# RL7005_IP_SVD register map
Vendor: Realtek
Registers are 32-bit, read-write, reset 0x0 unless marked. A register's access mark holds for its fields unless they carry their own. Offsets are from the block's base; [hi:lo] are bit positions; lines under a group give offsets from that group; {n}, {i} and the like mark numbered series.

## RXI300_REG
Base 0x41002000
Same registers: MPC1_S 0x51002200, MPC2_S 0x51002300, MPC3_S 0x51002400, PPC_S 0x51002500
0x00 NAME ro reset 0x52300 — RXI300 design name register
  [31:0] NAME — The design name of RXI-300.
0x04 VER ro reset 0x300 — RXI300 design version register
  [31:0] VER — The design version of RXI-300.
0x08 RVE ro reset 0x1 — RXI300 design reversion register
  [31:0] REV — The design reversion of RXI-300.
0x0C INST ro — RXI300 design instance number register
  [31:0] INST — The design instance number of RXI-300.
0x10 IMPL_Y ro reset 0x2024 — RXI300 implementation year register
  [31:0] IMPL_Y — The implementatin year of RXI-300. Reset value depends on implementation date.
0x14 IMPL_D ro reset 0x5101058 — RXI300 implementation date register
  [31:0] IMPL_D — The implementatin date of RXI-300. Reset value depends on implementation date.
0x18 DEV ro reset 0x5207433 — RXI300 developer register
  [31:0] DEV — The developer of RXI-300.
0x1C PRO_NUM ro reset 0x7005 — RXI300 project number register
  [31:0] PRO_NUM — The project number of RXI-300.
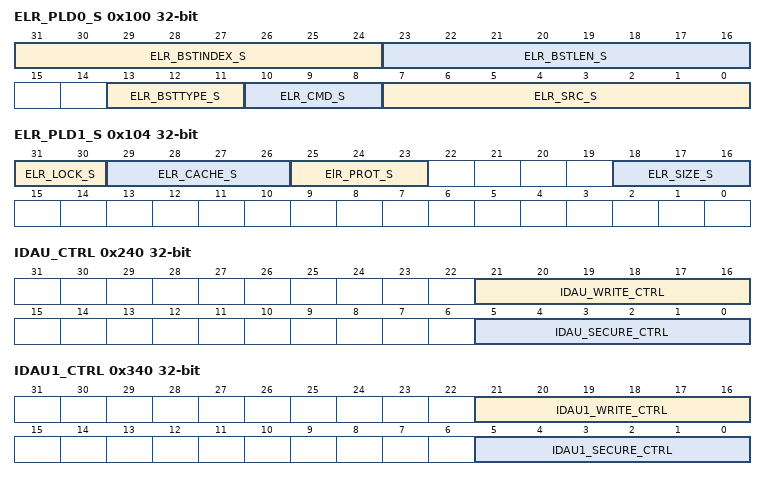
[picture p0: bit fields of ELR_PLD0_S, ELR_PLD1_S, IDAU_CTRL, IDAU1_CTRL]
0x100 ELR_PLD0_S ro — Error log payload register0
  [31:24] ELR_BSTINDEX_S — Burst index of the error request.
  [23:16] ELR_BSTLEN_S — Burst Length of the error request.
  [13:11] ELR_BSTTYPE_S — BurstSeq of the error request.
  [10:8] ELR_CMD_S — CMD of the error request. 0x1: Write command 0x2: Read command
  [7:0] ELR_SRC_S — Error source of the error request. 0x10: S1 securedefault slave 0x20: S2 securedefault slave 0x30: S3-0~1,5,7(AHB) group secure default slave 0x31: S3-2~4,6,13~22(AHB) group secure default slave 0x32: S3-8(AXI) secure default slave 0x33:S3-9~10(SPIC)group secure default slave 0x34: S3-11~12(PSRAM)group secure default slave 0x60: S4-0~6 secure default slave 0x61: S4-7~15 secure default slave 0x70: S5 secure default slave 0x71: MPC/PPC secure default slave 0x80: S8 secure default slave
0x104 ELR_PLD1_S ro — Error log payload register1
  [31:30] ELR_LOCK_S — AxLock of the error request.
  [29:26] ELR_CACHE_S — AxCache of the error request.
  [25:23] ElR_PROT_S — AxProt of the error request.
  [18:16] ELR_SIZE_S — Size of the error request.
0x108 ELR_ID_S ro — Error log ID information register
  [31:0] ELR_ID_S — Tagid of the error request. 9'b00000????: M0 access error 9'b00001????: M1 access error 9'b0100?????: M2 access error 9'b000110???: M3 access error 9'b0001010??: M4 access error 9'b000100110: M5-0 access error 9'b000100111: M5-1 access error 9'b0101?????: M6 access error 9'b1????????: M7 access error 9'b00010000?: M8 access error 9'b00010010: M9 access error 9'b00010001: M10 access error 9'b011000???: M11 access error
0x10C ELR_ADR0_S ro — Error log addrress register0
  [31:0] ELR_ADR0_S — Address[31:0] of the error request.
0x110 ELR_ADR1_S ro — Error log addrress register1
  [63:32] ELR_ADR1_S — Address[63:32] of the error request.
0x130 ELR_CODE_S ro — Error code register
  [7:0] ELR_CODE_S — The error code of error request, if it's 0, indicates that there is no error request. 8'h00: No error 8'h02: Secure fault error
0x13C ELR_INTR_CLR_S wo — Error log clear register
  [0] ELR_INTR_CLR_S — Error log interrupt clear. Writing 1'b1 to the register will trigger a 1-cycle pulse interrupt clear. It has to write 1'b1 to this register every time when the error exception occurs. Note that this register is write-only, the return value of reading this register is meaningless.
{0x200+8i} IDAU_BA{i} (i=0..5) — Base address register {i} in IDAU
  [27:12] IDAU_BA{i} — It's the base address of region {i} which can be set as non-secure. [11:0]: reserved [27:12]: base address of region {i} [31:28]: reserved
{0x204+8i} IDAU_LA{i} reset 0xFFFF000 (i=0..5) — Top address register {i} in IDAU
  [27:12] IDAU_LA{i} — It's the top address of region {i} which can be set as non-secure. [11:0]: reserved [27:12]: top address of region {i} [31:28]: reserved
0x240 IDAU_CTRL — Enable control register in IDAU
  [21:16] IDAU_WRITE_CTRL — Region entry enable After setting WRITE_CTRL bits as 1, corresponding regions is set as write-forbidden.Note that if WRITE_CTRL bits are enabled, the region remains secure even if ba*i/la*i is set. [16]: enable entry for ba0/la0 0: disable 1: enable [17]: enable entry for ba1/la1 0: disable 1: enable [18]: enable entry for ba2/la2 0: disable 1: enable [19]: enable entry for ba3/la3 0: disable 1: enable [20]: enable entry for ba4/la4 0: disable 1: enable [21]: enable entry for ba5/la5 0: disable 1: enable
  [5:0] IDAU_SECURE_CTRL — Region entry enable After setting SECURE_CTRL bits as 1, corresponding regions is set as non-secure.Note that if SECURE_CTRL bits are enabled, the region remains secure even if ba*i/la*i is set. [0]: enable entry for ba0/la0 0: disable 1: enable [1]: enable entry for ba1/la1 0: disable 1: enable [2]: enable entry for ba2/la2 0: disable 1: enable [3]: enable entry for ba3/la3 0: disable 1: enable [4]: enable entry for ba4/la4 0: disable 1: enable [5]: enable entry for ba5/la5 0: disable 1: enable
0x244 IDAU_LOCK — Lock control register in IDAU
  [0] IDAU_LOCK — Lock write transfer for all registers in IDAU (including lock register itself) until system reset if it is ebabled. 0: disable lock 1: enable lock
{0x300+8i} IDAU1_BA{i} (i=0..5) — Base address register {i} in IDAU1
  [27:12] IDAU1_BA{i} — It's the base address of region {i} which can be set as non-secure. [11:0]: reserved [27:12]: base address of region {i} [31:28]: reserved
{0x304+8i} IDAU1_LA{i} reset 0xFFFF000 (i=0..5) — Top address register {i} in IDAU1
  [27:12] IDAU1_LA{i} — It's the top address of region {i} which can be set as non-secure. [11:0]: reserved [27:12]: top address of region {i} [31:28]: reserved
0x340 IDAU1_CTRL — Enable control register in IDAU1
  [21:16] IDAU1_WRITE_CTRL — Region entry enable After setting WRITE_CTRL bits as 1, corresponding regions is set as write-forbidden.Note that if WRITE_CTRL bits are enabled, the region remains secure even if ba*i/la*i is set. [16]: enable entry for ba0/la0 0: disable 1: enable [17]: enable entry for ba1/la1 0: disable 1: enable [18]: enable entry for ba2/la2 0: disable 1: enable [19]: enable entry for ba3/la3 0: disable 1: enable [20]: enable entry for ba4/la4 0: disable 1: enable [21]: enable entry for ba5/la5 0: disable 1: enable
  [5:0] IDAU1_SECURE_CTRL — Region entry enable After setting SECURE_CTRL bits as 1, corresponding regions is set as non-secure.Note that if SECURE_CTRL bits are enabled, the region remains secure even if ba*i/la*i is set. [0]: enable entry for ba0/la0 0: disable 1: enable [1]: enable entry for ba1/la1 0: disable 1: enable [2]: enable entry for ba2/la2 0: disable 1: enable [3]: enable entry for ba3/la3 0: disable 1: enable [4]: enable entry for ba4/la4 0: disable 1: enable [5]: enable entry for ba5/la5 0: disable 1: enable
0x344 IDAU1_LOCK — Lock control register in IDAU1
  [0] IDAU1_LOCK — Lock write transfer for all registers in IDAU1 (including lock register itself) until system reset if it is ebabled. 0: disable lock 1: enable lock
{0x400+8i} IDAU2_BA{i} (i=0..5) — Base address register {i} in IDAU2
  [27:12] IDAU2_BA{i} — It's the base address of region {i} which can be set as non-secure. [11:0]: reserved [27:12]: base address of region {i} [31:28]: reserved
{0x404+8i} IDAU2_LA{i} reset 0xFFFF000 (i=0..5) — Top address register {i} in IDAU2
  [27:12] IDAU2_LA{i} — It's the top address of region {i} which can be set as non-secure. [11:0]: reserved [27:12]: top address of region {i} [31:28]: reserved
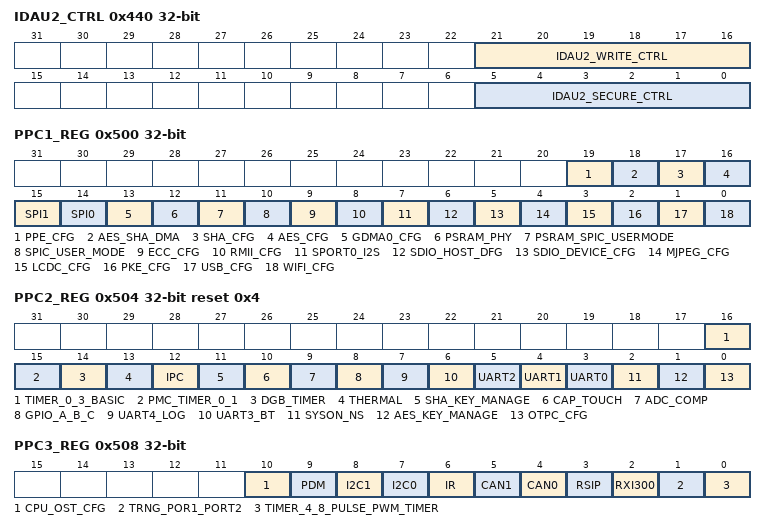
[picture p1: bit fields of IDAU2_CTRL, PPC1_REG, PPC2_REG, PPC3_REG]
0x440 IDAU2_CTRL — Enable control register in IDAU2
  [21:16] IDAU2_WRITE_CTRL — Region entry enable After setting WRITE_CTRL bits as 1, corresponding regions is set as write-forbidden.Note that if WRITE_CTRL bits are enabled, the region remains secure even if ba*i/la*i is set. [16]: enable entry for ba0/la0 0: disable 1: enable [17]: enable entry for ba1/la1 0: disable 1: enable [18]: enable entry for ba2/la2 0: disable 1: enable [19]: enable entry for ba3/la3 0: disable 1: enable [20]: enable entry for ba4/la4 0: disable 1: enable [21]: enable entry for ba5/la5 0: disable 1: enable
  [5:0] IDAU2_SECURE_CTRL — Region entry enable After setting SECURE_CTRL bits as 1, corresponding regions is set as non-secure.Note that if SECURE_CTRL bits are enabled, the region remains secure even if ba*i/la*i is set. [0]: enable entry for ba0/la0 0: disable 1: enable [1]: enable entry for ba1/la1 0: disable 1: enable [2]: enable entry for ba2/la2 0: disable 1: enable [3]: enable entry for ba3/la3 0: disable 1: enable [4]: enable entry for ba4/la4 0: disable 1: enable [5]: enable entry for ba5/la5 0: disable 1: enable
0x444 IDAU2_LOCK — Lock control register in IDAU2
  [0] IDAU2_LOCK — Lock write transfer for all registers in IDAU2 (including lock register itself) until system reset if it is ebabled. 0: disable lock 1: enable lock
0x500 PPC1_REG — PPC1 configure register0
  [19] PPE_CFG — 1: Non-secure attribution 0: Secure attribution
  [18] AES_SHA_DMA — 1: Non-secure attribution 0: Secure attribution
  [17] SHA_CFG — 1: Non-secure attribution 0: Secure attribution
  [16] AES_CFG — 1: Non-secure attribution 0: Secure attribution
  [15] SPI1 — 1: Non-secure attribution 0: Secure attribution
  [14] SPI0 — 1: Non-secure attribution 0: Secure attribution
  [13] GDMA0_CFG — 1: Non-secure attribution 0: Secure attribution
  [12] PSRAM_PHY — 1: Non-secure attribution 0: Secure attribution
  [11] PSRAM_SPIC_USERMODE — 1: Non-secure attribution 0: Secure attribution
  [10] SPIC_USER_MODE — 1: Non-secure attribution 0: Secure attribution
  [9] ECC_CFG — 1: Non-secure attribution 0: Secure attribution
  [8] RMII_CFG — 1: Non-secure attribution 0: Secure attribution
  [7] SPORT0_I2S — 1: Non-secure attribution 0: Secure attribution
  [6] SDIO_HOST_DFG — 1: Non-secure attribution 0: Secure attribution
  [5] SDIO_DEVICE_CFG — 1: Non-secure attribution 0: Secure attribution
  [4] MJPEG_CFG — 1: Non-secure attribution 0: Secure attribution
  [3] LCDC_CFG — 1: Non-secure attribution 0: Secure attribution
  [2] PKE_CFG — 1: Non-secure attribution 0: Secure attribution
  [1] USB_CFG — 1: Non-secure attribution 0: Secure attribution
  [0] WIFI_CFG — 1: Non-secure attribution 0: Secure attribution
0x504 PPC2_REG reset 0x4 — PPC2 configure register
  [16] TIMER_0_3_BASIC — 1: Non-secure attribution 0: Secure attribution
  [15] PMC_TIMER_0_1 — 1: Non-secure attribution 0: Secure attribution
  [14] DGB_TIMER — 1: Non-secure attribution 0: Secure attribution
  [13] THERMAL — 1: Non-secure attribution 0: Secure attribution
  [12] IPC — 1: Non-secure attribution 0: Secure attribution
  [11] SHA_KEY_MANAGE — 1: Non-secure attribution 0: Secure attribution
  [10] CAP_TOUCH — 1: Non-secure attribution 0: Secure attribution
  [9] ADC_COMP — 1: Non-secure attribution 0: Secure attribution
  [8] GPIO_A_B_C — 1: Non-secure attribution 0: Secure attribution
  [7] UART4_LOG — 1: Non-secure attribution 0: Secure attribution
  [6] UART3_BT — 1: Non-secure attribution 0: Secure attribution
  [5] UART2 — 1: Non-secure attribution 0: Secure attribution
  [4] UART1 — 1: Non-secure attribution 0: Secure attribution
  [3] UART0 — 1: Non-secure attribution 0: Secure attribution
  [2] SYSON_NS — 1: Non-secure attribution 0: Secure attribution
  [1] AES_KEY_MANAGE — 1: Non-secure attribution 0: Secure attribution
  [0] OTPC_CFG — 1: Non-secure attribution 0: Secure attribution
0x508 PPC3_REG — PPC3 configure register
  [10] CPU_OST_CFG — 1: Non-secure attribution 0: Secure attribution
  [9] PDM — 1: Non-secure attribution 0: Secure attribution
  [8] I2C1 — 1: Non-secure attribution 0: Secure attribution
  [7] I2C0 — 1: Non-secure attribution 0: Secure attribution
  [6] IR — 1: Non-secure attribution 0: Secure attribution
  [5] CAN1 — 1: Non-secure attribution 0: Secure attribution
  [4] CAN0 — 1: Non-secure attribution 0: Secure attribution
  [3] RSIP — 1: Non-secure attribution 0: Secure attribution
  [2] RXI300 — 1: Non-secure attribution 0: Secure attribution
  [1] TRNG_POR1_PORT2 — 1: Non-secure attribution 0: Secure attribution
  [0] TIMER_4_8_PULSE_PWM_TIMER — 1: Non-secure attribution 0: Secure attribution
0x50C PPC_LOCK
  [0] LOCK — PPC lock register. When writing 1'b1 to this nit, PPC will be locked. Note: It can not be written to 1'b0 again until system reset to prevent modification. When PPC is locked, you can not program PPC registers unless system reset.
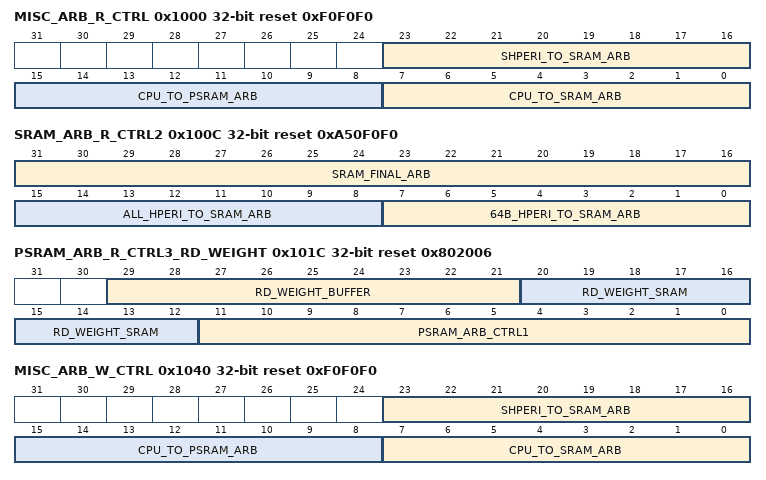
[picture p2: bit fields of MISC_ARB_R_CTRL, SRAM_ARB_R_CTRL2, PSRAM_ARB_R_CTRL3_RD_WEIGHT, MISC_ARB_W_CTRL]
0x1000 MISC_ARB_R_CTRL reset 0xF0F0F0 — The register for CPU/HPERI to SRAM/PSRAM read arbitration
  [23:16] SHPERI_TO_SRAM_ARB — Read arbitration control register. Each slot should be set by a port number. The port number represents a master group.The master group is shown as following: 0x0: LCDC 0x1: PPE And the following shows bit field of each slots: [0]: slot 0 of arbiter [1]: slot 1 of arbiter [2]: slot 2 of arbiter [3]: slot 3 of arbiter [4]: slot 4 of arbiter [5]: slot 5 of arbiter [6]: slot 6 of arbiter [7]: slot 7 of arbiter
  [15:8] CPU_TO_PSRAM_ARB — Read arbitration control register. Each slot should be set by a port number. The port number represents a master group.The master group is shown as following: 0x0: CPU0 0x1: CPU1 And the following shows bit field of each slots: [0]: slot 0 of arbiter [1]: slot 1 of arbiter [2]: slot 2 of arbiter [3]: slot 3 of arbiter [4]: slot 4 of arbiter [5]: slot 5 of arbiter [6]: slot 6 of arbiter [7]: slot 7 of arbiter
  [7:0] CPU_TO_SRAM_ARB — Read arbitration control register. Each slot should be set by a port number. The port number represents a master group.The master group is shown as following: 0x0: CPU0 0x1: CPU1 And the following shows bit field of each slots: [0]: slot 0 of arbiter [1]: slot 1 of arbiter [2]: slot 2 of arbiter [3]: slot 3 of arbiter [4]: slot 4 of arbiter [5]: slot 5 of arbiter [6]: slot 6 of arbiter [7]: slot 7 of arbiter
0x1004 SRAM_ARB_R_CTRL0 reset 0x2D91A240 — The register for 32-bit HPERI master group to SRAM read arbitration
  [29:0] 32B_HPERI_TO_SRAM_ARB — Read arbitration control register. Each slot should be set by a port number. The port number represents a master group.The master group is shown as following: 0x0: GDMA 0x1: WIFI 0x2: USB/SDIO_BT/SDIO_WIFI 0x3: OTPC/SIC 0x4: SDIO_HOST 0x5: RMII And the following shows bit field of each slots: [2:0]: slot 0 of arbiter [5:3]: slot 1 of arbiter [8:6]: slot 2 of arbiter [11:9]: slot 3 of arbiter [14:12]: slot 4 of arbiter [17:15]: slot 5 of arbiter [20:18]: slot 6 of arbiter [23:21]: slot 7 of arbiter [26:24]: slot 8 of arbiter [29:27]: slot 9 of arbiter
0x1008 SRAM_ARB_R_CTRL1 reset 0x2D91A240 — The register for 32-bit HPERI master group to SRAM read arbitration
  [29:0] 32B_HPERI_TO_SRAM_ARB — This is extended register of 32B_HPERI_TO_SRAM_ARB [2:0]: slot 0 of arbiter [5:3]: slot 1 of arbiter [8:6]: slot 2 of arbiter [11:9]: slot 3 of arbiter [14:12]: slot 4 of arbiter [17:15]: slot 5 of arbiter [20:18]: slot 6 of arbiter [23:21]: slot 7 of arbiter [26:24]: slot 8 of arbiter [29:27]: slot 9 of arbiter
0x100C SRAM_ARB_R_CTRL2 reset 0xA50F0F0 — The register for CPU/LCDC/HPERI master group to SRAM read arbitration
  [31:16] SRAM_FINAL_ARB — Read arbitration control register. Each slot should be set by a port number. The port number represents a master group.The master group is shown as following: 0x0: CPU_TO_SRAM_ARB group 0x1: ALL_HPERI_TO_SRAM_ARB group 0x2: SHPERI_TO_SRAM_ARB group And the following shows bit field of each slots: [1:0]: slot 0 of arbiter [3:2]: slot 1 of arbiter [5:4]: slot 2 of arbiter [7:6]: slot 3 of arbiter [9:8]: slot 4 of arbiter [11:10]: slot 5 of arbiter [13:12]: slot 6 of arbiter [15:14]: slot 7 of arbiter
  [15:8] ALL_HPERI_TO_SRAM_ARB — Read arbitration control register. Each slot should be set by a port number. The port number represents a master group.The master group is shown as following: 0x0: 32B_HPERI_TO_SRAM_ARB group 0x1: 64B_HPERI_TO_SRAM_ARB group And the following shows bit field of each slots: [0]: slot 0 of arbiter [1]: slot 1 of arbiter [2]: slot 2 of arbiter [3]: slot 3 of arbiter [4]: slot 4 of arbiter [5]: slot 5 of arbiter [6]: slot 6 of arbiter [7]: slot 7 of arbiter
  [7:0] 64B_HPERI_TO_SRAM_ARB — Read arbitration control register. Each slot should be set by a port number. The port number represents a master group.The master group is shown as following: 0x0: AES_SHA 0x1: MJPEG And the following shows bit field of each slots: [0]: slot 0 of arbiter [1]: slot 1 of arbiter [2]: slot 2 of arbiter [3]: slot 3 of arbiter [4]: slot 4 of arbiter [5]: slot 5 of arbiter [6]: slot 6 of arbiter [7]: slot 7 of arbiter
0x1010 PSRAM_ARB_R_CTRL0 reset 0x246D2240 — The register for no performance requirement master group to PSRAM read arbitration
  [29:0] HPERI_TO_PSRAM_ARB — Read arbitration control register. Each slot should be set by a port number. The port number represents a master group.The master group is shown as following: 0x0: GDMA 0x1: OTPC/SIC 0x2: AED_SHA 0x3: SDIO_HOST 0x4: RMII And the following shows bit field of each slots: [2:0]: slot 0 of arbiter [5:3]: slot 1 of arbiter [8:6]: slot 2 of arbiter [11:9]: slot 3 of arbiter [14:12]: slot 4 of arbiter [17:15]: slot 5 of arbiter [20:18]: slot 6 of arbiter [23:21]: slot 7 of arbiter [26:24]: slot 8 of arbiter [29:27]: slot 9 of arbiter
0x1014 PSRAM_ARB_R_CTRL1 reset 0x1A489200 — The register for PSRAM read arbitration
  [29:0] R_CTRL1_PSRAM_FINAL_ARB — Read arbitration control register. Each slot should be set by a port number. The port number represents a master group.The master group is shown as following: 0x0: CPU0/CPU1 0x1: HPERI_TO_PSRAM_ARB group 0x2: WIFI 0x3: USB 0x4: MJPEG 0x5: LCDC 0x6: PPE And the following shows bit field of each slots: [2:0]: slot 0 of arbiter [5:3]: slot 1 of arbiter [8:6]: slot 2 of arbiter [11:9]: slot 3 of arbiter [14:12]: slot 4 of arbiter [17:15]: slot 5 of arbiter [20:18]: slot 6 of arbiter [23:21]: slot 7 of arbiter [26:24]: slot 8 of arbiter [29:27]: slot 9 of arbiter
0x1018 PSRAM_ARB_R_CTRL2 reset 0x36B6C91B — The register for PSRAM read arbitration
  [29:0] R_CTRL2_PSRAM_FINAL_ARB — This is extended register of PSRAM_FINAL_ARB slot [2:0]: slot 10 of arbiter [5:3]: slot 11 of arbiter [8:6]: slot 12 of arbiter [11:9]: slot 13 of arbiter [14:12]: slot 14 of arbiter [17:15]: slot 15 of arbiter [20:18]: slot 16 of arbiter [23:21]: slot 17 of arbiter [26:24]: slot 18 of arbiter [29:27]: slot 19 of arbiter
0x101C PSRAM_ARB_R_CTRL3_RD_WEIGHT reset 0x802006 — The register for PSRAM read arbitration and weight control of SRAM controller
  [29:21] RD_WEIGHT_BUFFER — Read CMD weight of buffer_ram
  [20:12] RD_WEIGHT_SRAM — Read CMD weight of hs_sram0
  [11:0] PSRAM_ARB_CTRL1 — This is extended register of PSRAM_ARB_CTRL0 slot. [3:0]: slot 8 of arbiter [7:4]: slot 9 of arbiter [11:8]: slot 10 of arbiter [15:12]: slot 11 of arbiter [19:16]: slot 12 of arbiter [23:20]: slot 13 of arbiter [27:24]: slot 14 of arbiter [31:28]: slot 15 of arbiter
0x1040 MISC_ARB_W_CTRL reset 0xF0F0F0 — The register for CPU/SHPERI to SRAM/PSRAM write arbitration
  [23:16] SHPERI_TO_SRAM_ARB — Write arbitration control register. Each slot should be set by a port number. The port number represents a master group.The master group is shown as following: 0x0: LCDC 0x1: PPE And the following shows bit field of each slots: [0]: slot 0 of arbiter [1]: slot 1 of arbiter [2]: slot 2 of arbiter [3]: slot 3 of arbiter [4]: slot 4 of arbiter [5]: slot 5 of arbiter [6]: slot 6 of arbiter [7]: slot 7 of arbiter
  [15:8] CPU_TO_PSRAM_ARB — Write arbitration control register. Each slot should be set by a port number. The port number represents a master group.The master group is shown as following: 0x0: CPU0 0x1: CPU1 And the following shows bit field of each slots: [0]: slot 0 of arbiter [1]: slot 1 of arbiter [2]: slot 2 of arbiter [3]: slot 3 of arbiter [4]: slot 4 of arbiter [5]: slot 5 of arbiter [6]: slot 6 of arbiter [7]: slot 7 of arbiter
  [7:0] CPU_TO_SRAM_ARB — Write arbitration control register. Each slot should be set by a port number. The port number represents a master group.The master group is shown as following: 0x0: CPU0 0x1: CPU1 And the following shows bit field of each slots: [0]: slot 0 of arbiter [1]: slot 1 of arbiter [2]: slot 2 of arbiter [3]: slot 3 of arbiter [4]: slot 4 of arbiter [5]: slot 5 of arbiter [6]: slot 6 of arbiter [7]: slot 7 of arbiter
0x1044 SRAM_ARB_W_CTRL0 reset 0x2D91A240 — The register 32-bit HPERI master group to SRAM write arbitration
  [29:0] 32B_HPERI_TO_SRAM_ARB — Write arbitration control register. Each slot should be set by a port number. The port number represents a master group.The master group is shown as following: 0x0: GDMA 0x1: WIFI 0x2: USB/SDIO_BT/SDIO_WIFI 0x3: OTPC/SIC 0x4: SDIO_HOST 0x5: RMII And the following shows bit field of each slots: [2:0]: slot 0 of arbiter [5:3]: slot 1 of arbiter [8:6]: slot 2 of arbiter [11:9]: slot 3 of arbiter [14:12]: slot 4 of arbiter [17:15]: slot 5 of arbiter [20:18]: slot 6 of arbiter [23:21]: slot 7 of arbiter [26:24]: slot 8 of arbiter [29:27]: slot 9 of arbiter
0x1048 SRAM_ARB_W_CTRL1 reset 0x2D91A240 — The register 32-bit HPERI master group to SRAM write arbitration
  [29:0] 32B_HPERI_TO_SRAM_ARB — This is extended register of 32B_HPERI_TO_SRAM_ARB [2:0]: slot 10 of arbiter [5:3]: slot 11 of arbiter [8:6]: slot 12 of arbiter [11:9]: slot 13 of arbiter [14:12]: slot 14 of arbiter [17:15]: slot 15 of arbiter [20:18]: slot 16 of arbiter [23:21]: slot 17 of arbiter [26:24]: slot 18 of arbiter [29:27]: slot 19 of arbiter
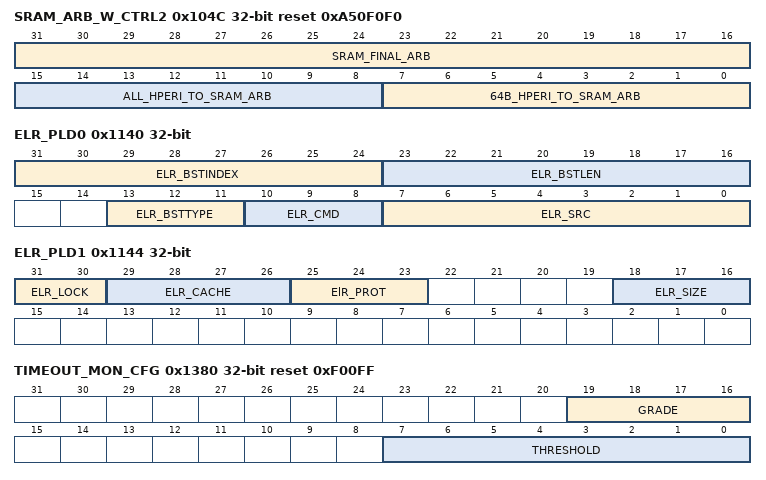
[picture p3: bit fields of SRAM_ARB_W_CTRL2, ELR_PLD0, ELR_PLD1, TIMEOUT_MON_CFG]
0x104C SRAM_ARB_W_CTRL2 reset 0xA50F0F0 — The register for CPU/LCD/ HPERI master group to SRAM write arbitration
  [31:16] SRAM_FINAL_ARB — Write arbitration control register. Each slot should be set by a port number. The port number represents a master group.The master group is shown as following: 0x0: CPU_TO_SRAM_ARB group 0x1: ALL_HPERI_TO_SRAM_ARB group 0x2: SHPERI_TO_SRAM_ARB group And the following shows bit field of each slots: [1:0]: slot 0 of arbiter [3:2]: slot 1 of arbiter [5:4]: slot 2 of arbiter [7:6]: slot 3 of arbiter [9:8]: slot 4 of arbiter [11:10]: slot 5 of arbiter [13:12]: slot 6 of arbiter [15:14]: slot 7 of arbiter
  [15:8] ALL_HPERI_TO_SRAM_ARB — Write arbitration control register. Each slot should be set by a port number. The port number represents a master group.The master group is shown as following: 0x0: 32B_HPERI_TO_SRAM_ARB group 0x1: 64B_HPERI_TO_SRAM_ARB group And the following shows bit field of each slots: [0]: slot 0 of arbiter [1]: slot 1 of arbiter [2]: slot 2 of arbiter [3]: slot 3 of arbiter [4]: slot 4 of arbiter [5]: slot 5 of arbiter [6]: slot 6 of arbiter [7]: slot 7 of arbiter
  [7:0] 64B_HPERI_TO_SRAM_ARB — Write arbitration control register. Each slot should be set by a port number. The port number represents a master group.The master group is shown as following: 0x0: AES_SHA 0x1: MJPEG And the following shows bit field of each slots: [0]: slot 0 of arbiter [1]: slot 1 of arbiter [2]: slot 2 of arbiter [3]: slot 3 of arbiter [4]: slot 4 of arbiter [5]: slot 5 of arbiter [6]: slot 6 of arbiter [7]: slot 7 of arbiter
0x1050 PSRAM_ARB_W_CTRL0 reset 0x246D2240 — The register for performance requirement master group to PSRAM write arbitration
  [29:0] HPERI_TO_PSRAM_ARB — Write arbitration control register. Each slot should be set by a port number. The port number represents a master group.The master group is shown as following: 0x0: GDMA 0x1: OTPC/SIC 0x2: AED_SHA 0x3: SDIO_HOST 0x4: RMII And the following shows bit field of each slots: [2:0]: slot 0 of arbiter [5:3]: slot 1 of arbiter [8:6]: slot 2 of arbiter [11:9]: slot 3 of arbiter [14:12]: slot 4 of arbiter [17:15]: slot 5 of arbiter [20:18]: slot 6 of arbiter [23:21]: slot 7 of arbiter [26:24]: slot 8 of arbiter [29:27]: slot 9 of arbiter
0x1054 PSRAM_ARB_W_CTRL1 reset 0x1A489200 — The register for PSRAM write arbitration
  [29:0] W_CTRL1_PSRAM_FINAL_ARB — Write arbitration control register. Each slot should be set by a port number. The port number represents a master group.The master group is shown as following: 0x0: CPU0/CPU1 0x1: HPERI_TO_PSRAM_ARB group 0x2: WIFI 0x3: USB 0x4: MJPEG 0x5: LCDC 0x6: PPE And the following shows bit field of each slots: [2:0]: slot 0 of arbiter [5:3]: slot 1 of arbiter [8:6]: slot 2 of arbiter [11:9]: slot 3 of arbiter [14:12]: slot 4 of arbiter [17:15]: slot 5 of arbiter [20:18]: slot 6 of arbiter [23:21]: slot 7 of arbiter [26:24]: slot 8 of arbiter [29:27]: slot 9 of arbiter
0x1058 PSRAM_ARB_W_CTRL2 reset 0x36B6C91B — The register for PSRAM write arbitration
  [29:0] W_CTRL2_PSRAM_FINAL_ARB — This is extended register of PSRAM_FINAL_ARB slot [2:0]: slot 10 of arbiter [5:3]: slot 11 of arbiter [8:6]: slot 12 of arbiter [11:9]: slot 13 of arbiter [14:12]: slot 14 of arbiter [17:15]: slot 15 of arbiter [20:18]: slot 16 of arbiter [23:21]: slot 17 of arbiter [26:24]: slot 18 of arbiter [29:27]: slot 19 of arbiter
0x105C PSRAM_ARB_W_CTRL3 reset 0x6 — The register for PSRAM write arbitration
  [11:0] W_CTRL3_PSRAM_FINAL_ARB — This is extended register of PSRAM_FINAL_ARB slot. [2:0]: slot 20 of arbiter [5:3]: slot 21 of arbiter [8:6]: slot 22 of arbiter [11:9]: slot 23 of arbiter
0x1140 ELR_PLD0 ro — Error log payload register0
  [31:24] ELR_BSTINDEX — Burst index of the error request.
  [23:16] ELR_BSTLEN — Burst Length of the error request.
  [13:11] ELR_BSTTYPE — BurstSeq of the error request.
  [10:8] ELR_CMD — CMD of the error request. 0x1: Write command 0x2: Read command
  [7:0] ELR_SRC — Error source of the error request. 0x90: timeout default slave of S6 group
0x1144 ELR_PLD1 ro — Error log payload register1
  [31:30] ELR_LOCK — AxLock of the error request.
  [29:26] ELR_CACHE — AxCache of the error request.
  [25:23] ElR_PROT — AxProt of the error request.
  [18:16] ELR_SIZE — Size of the error request.
0x1148 ELR_ID ro — Error log ID information register
  [31:0] ELR_ID — Tagid of the error request. 9'b00001????: M1 access error 9'b000100110: M5-0 access error 9'b000100111: M5-1 access error
0x114C ELR_ADR0 ro — Error log addrress register0
  [31:0] ELR_ADR0 — Address[31:0] of the error request.
0x1150 ELR_ADR1 ro — Error log addrress register1
  [63:32] ELR_ADR1 — Address[63:32] of the error request.
0x1170 ELR_CODE ro — Error code register
  [7:0] ELR_CODE — The error code of error request, if it's 0, indicates that there is no error request. 8'h00: No error 8'h01: Address hole error
0x117C ELR_INTR_CLR wo — Error log clear register
  [0] ELR_INTR_CLR — Error log interrupt clear. Writing 1'b1 to the register will trigger a 1-cycle pulse interrupt clear. It has to write 1'b1 to this register every time when the error exception occurs. Note that this register is write-only, the return value of reading this register is meaningless.
0x1300 TIMEOUT_GUARD_EN — Timeout guardian enable register
  [7:0] GUARDIAN_MODE_EN — The enable of timeout monitor group 0x0: Disable timeout check feature 0x1: Enable timeoute check feature
0x1340 TIMEOUT_CLEAN_N reset 0x1 — Timeout clear register
  [0] TIMEOUT_CLEAR_N — The register can only written to 0 when a time out occures, and automatically clear this register by hardware
0x1380 TIMEOUT_MON_CFG reset 0xF00FF — Timeout monitor configuration register0
  [19:16] GRADE — Timeout grade Timeout total cycle = [256*(2^(grade-1) +1)*threshold] - inaccurate Note: the range of inaccurate = 0 ~ [256*(2^(grade-1) +1)-2]
  [7:0] THRESHOLD — Timeout threshold
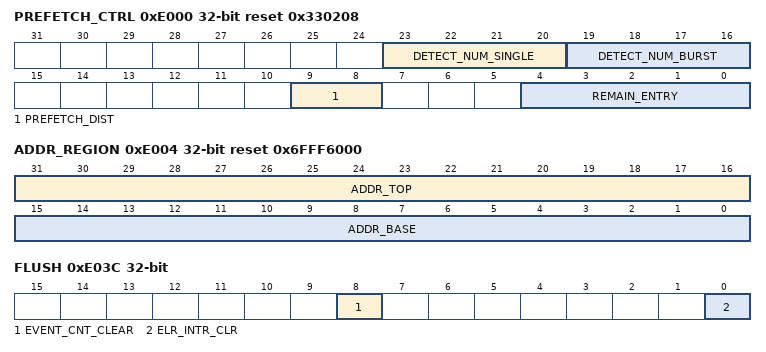
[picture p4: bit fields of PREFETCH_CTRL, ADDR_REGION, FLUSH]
0xE000 PREFETCH_CTRL reset 0x330208 — Prefetch control setting of stream buffer
  [23:20] DETECT_NUM_SINGLE — The number of required sequential single accesses before initiating prefetch
  [19:16] DETECT_NUM_BURST — The number of required sequential cache line accesses before initiating prefetch
  [9:8] PREFETCH_DIST — The size of prefech data 2'b00: no prefetch 2'h01: one cache line 2'h1?: two cache line
  [4:0] REMAIN_ENTRY — The remaining number of valid entries in the stream buffer required before automatically intiating prefetch.(support up to 16)
0xE004 ADDR_REGION reset 0x6FFF6000 — The address region that requires prefetch
  [31:16] ADDR_TOP — The top address boundary of prefetch. (only consider address[31:16])
  [15:0] ADDR_BASE — The base address boundary of prefetch. (only consider address[31:16])
0xE008 EVENT_CTRL reset 0x1 — Enable event counter
  [0] EVENT_CTRL_EN — Enable event counter.
0xE020 EVENT_CMD_CNT ro — The number of master conmmand
  [23:0] CMD_NUM — The number of master command
0xE024 EVENT_PREFETCH_CNT ro — The number of prefetch
  [23:0] PREFETCH_NUM
0xE028 EVENT_PREFETCH_HIT_CNT ro — The number of cache line hits after prefetch
  [23:0] PREFETCH_HIT — The number of transfer data is not immediately returned after cache line hits in ther stream buffer
0xE02C EVENT_DATA_DELAY_CNT ro — The number of transfer data is not immediately returned after cache line hits in the stream buffer
  [23:0] DATA_DELAY — The number of cache line hits after prefetch
0xE030 FLUSH_DONE ro — Indicate flush is complete
  [0] FLUSH_DONE
0xE03C FLUSH wo — Flush FIFO or event counter
  [8] EVENT_CNT_CLEAR — Clear event counter
  [0] ELR_INTR_CLR — Flush FIFO
